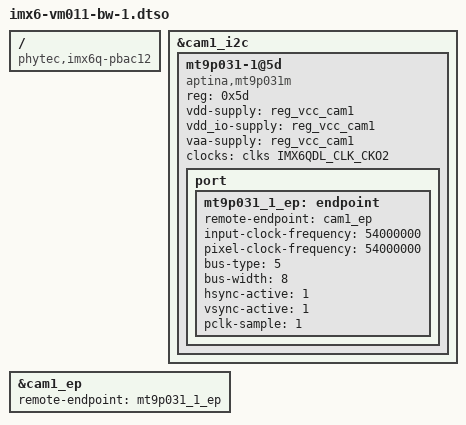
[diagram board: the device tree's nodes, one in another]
// SPDX-License-Identifier: (GPL-2.0+ OR MIT)
/*
 * Copyright (C) 2021 PHYTEC Messtechnik GmbH
 * Author: Stefan Riedmueller <s.riedmueller@phytec.de>
 */

/dts-v1/;
/plugin/;

#include <dt-bindings/clock/imx6qdl-clock.h>

/ {
	compatible = "phytec,imx6q-pbac12", "phytec,imx6dl-pbac12",
		     "phytec,imx6q-pbac06", "phytec,imx6dl-pbac06",
		     "phytec,imx6q-pbab01", "phytec,imx6dl-pbab01";
};

&cam1_i2c {
	mt9p031-1@5d {
		compatible = "aptina,mt9p031m";
		reg = <0x5d>;

		vdd-supply = <&reg_vcc_cam1>;
		vdd_io-supply = <&reg_vcc_cam1>;
		vaa-supply = <&reg_vcc_cam1>;

		clocks = <&clks IMX6QDL_CLK_CKO2>;

		port {
			mt9p031_1_ep: endpoint {
				remote-endpoint = <&cam1_ep>;
				input-clock-frequency = <54000000>;
				pixel-clock-frequency = <54000000>;
				bus-type = <5>; /* Parallel */
				bus-width = <8>;
				hsync-active = <1>;
				vsync-active = <1>;
				pclk-sample = <1>;
			};
		};
	};
};

&cam1_ep {
        remote-endpoint = <&mt9p031_1_ep>;
};
